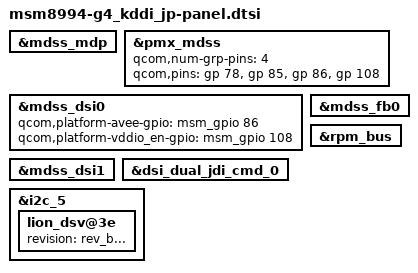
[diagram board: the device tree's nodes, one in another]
/* Copyright (c) 2014, The Linux Foundation. All rights reserved.
 *
 * This program is free software; you can redistribute it and/or modify
 * it under the terms of the GNU General Public License version 2 and
 * only version 2 as published by the Free Software Foundation.
 *
 * This program is distributed in the hope that it will be useful,
 * but WITHOUT ANY WARRANTY; without even the implied warranty of
 * MERCHANTABILITY or FITNESS FOR A PARTICULAR PURPOSE.  See the
 * GNU General Public License for more details.
 */

#include "../msm8994-g4_common/msm8994-common-panel.dtsi"

//copy from msm8994-cdp.dtsi and modify.


&mdss_mdp {

};

&pmx_mdss {
	qcom,num-grp-pins = <4>;
	qcom,pins = <&gp 78>, <&gp 85>, <&gp 86>, <&gp 108>;
};

&mdss_dsi0 {

	qcom,platform-avee-gpio = <&msm_gpio 86 0>;
	qcom,platform-vddio_en-gpio = <&msm_gpio 108 0>;

};

&mdss_fb0 {

};

&mdss_dsi1 {


};

&dsi_dual_jdi_cmd_0{

};

/* RPM controlled regulators: */

&rpm_bus {

};

&i2c_5 {
    lion_dsv@3e {
        status = "ok";
        revision = "rev_b...";

    };
};
